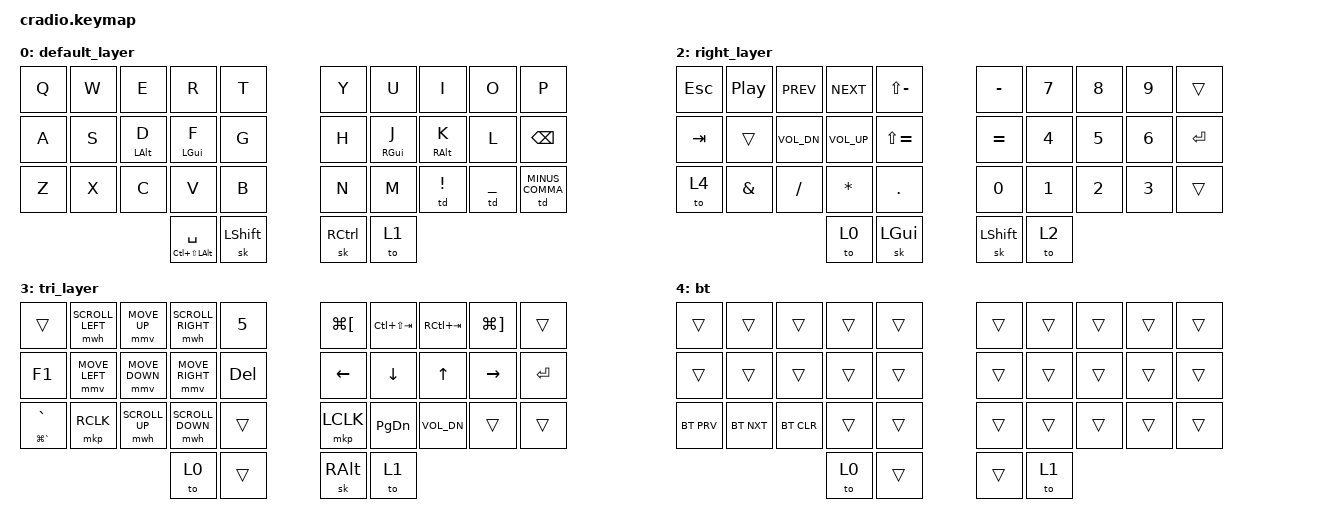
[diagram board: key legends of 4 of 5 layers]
/*
 * Copyright (c) 2020 The ZMK Contributors
 *
 * SPDX-License-Identifier: MIT
 */

#include <behaviors.dtsi>
#include <dt-bindings/zmk/keys.h>
#include <dt-bindings/zmk/bt.h>
#include <dt-bindings/zmk/mouse.h>

/* Configure behavior for mod-tap (mt) keys */
&mt {
    flavor = "tap-preferred";
    tapping_term_ms = <200>;
};

/* Configure behavior for mouse movement */
&mmv {
   time-to-max-speed-ms = <680>;
   acceleration-exponent=<2>;
};

/ {

    /* Define custom behaviors */
    behaviors {
        hm: homerow_mods {
            compatible = "zmk,behavior-hold-tap";
            label = "HOMEROW_MODS";
            #binding-cells = <2>;
            tapping-term-ms = <200>;
            quick_tap_ms = <0>;
            flavor = "tap-preferred";
            bindings = <&kp>, <&kp>;
        };
        td: tapdance {
            compatible = "zmk,behavior-hold-tap";
            label = "TAPDANCE";
            #binding-cells = <2>;
            tapping-term-ms = <150>;
            quick_tap_ms = <0>;
            flavor = "tap-preferred";
            bindings = <&kp>, <&kp>;
        };
    };

    /* Define the keymap */
    keymap {
        compatible = "zmk,keymap";

        /* Default layer - QWERTY layout with some modifiers */
        default_layer {
        /* 
         * ┌─────────┬─────────┬─────────┬─────────┬─────────┐            ┌─────────┬─────────┬─────────┬─────────┬─────────┐
         * │    Q    │    W    │    E    │    R    │    T    │            │    Y    │    U    │    I    │    O    │    P    │
         * ├─────────┼─────────┼─────────┼─────────┼─────────┤            ├─────────┼─────────┼─────────┼─────────┼─────────┤
         * │    A    │    S    │  Alt/D  │  GUI/F  │    G    │            │    H    │  GUI/J  │  Alt/K  │    L    │  Bksp   │
         * ├─────────┼─────────┼─────────┼─────────┼─────────┤            ├─────────┼─────────┼─────────┼─────────┼─────────┤
         * │    Z    │    X    │    C    │    V    │    B    │            │    N    │    M    │    !    │    _    │   - ,   │
         * └─────────┴─────────┴─────────┴─────────┴─────────┘            └─────────┴─────────┴─────────┴─────────┴─────────┘
         *                 LCtrl/Tap     Space/Tap                                LShift                RCtrl    Layer 1
         */

        bindings = <

        /* Row 1 */
        &kp Q      &kp W      &kp E      &kp R      &kp T              &kp Y      &kp U      &kp I      &kp O      &kp P
        
        /* Row 2 */
        &kp A      &kp S      &hm LALT D &hm LGUI F &kp G              &kp H      &hm RGUI J &hm RALT K &kp L      &kp BKSP

        /* Row 3 */
        &kp Z      &kp X      &kp C      &kp V      &kp B              &kp N      &kp M      &td EXCL   &td UNDERSCORE &td MINUS_COMMA

        /* Bottom row */
                          &mt LC(LS(LALT)) SPC &sk LSHIFT              &sk RCTRL  &to 1
        >;
        };

        /* Left-hand layer for special characters and numbers */
        left_layer {
        /* 
         * ┌─────────┬─────────┬─────────┬─────────┬─────────┐            ┌─────────┬─────────┬─────────┬─────────┬─────────┐
         * │   Esc   │    @    │   #3    │   $     │    %    │            │   ^     │    ,    │    .    │    ;    │  Bksp   │
         * ├─────────┼─────────┼─────────┼─────────┼─────────┤            ├─────────┼─────────┼─────────┼─────────┼─────────┤
         * │   Tab   │   =     │   [     │   {     │    '    │            │   \     │    [    │    ]    │   |     │  Enter  │
         * ├─────────┼─────────┼─────────┼─────────┼─────────┤            ├─────────┼─────────┼─────────┼─────────┼─────────┤
         * │   ~     │    3    │   {     │   }     │    "    │            │   (     │    )    │    ]    │   -> L3 │
         * └─────────┴─────────┴─────────┴─────────┴─────────┘            └─────────┴─────────┴─────────┴─────────┴─────────┘
         *               Layer 0         Shift                                RAlt      Layer 2
         */
        bindings = <
        &kp ESC     &kp ATSN  &td LC(LG(LS(N4))) LS(N3) &kp DLLR    &kp PRCNT  
        &kp CARET   &kp LS(COMMA) &kp LS(DOT)  &kp SEMI   &kp BKSP

        &kp TAB     &kp EQUAL &kp LA(RBKT)    &kp LA(LS(RBKT))  &kp SQT   
        &kp BSLH    &kp LBRC  &kp RBRC        &kp PIPE          &kp ENTER

        &kp TILDE   &kp LA(N3) &kp LA(LBKT)   &kp LA(LS(LBKT))  &kp DQT  
        &kp LBKT    &kp LPRN  &kp RPRN        &kp RBKT          &to 3

                          &to 0              &sk LSHIFT        &sk RALT          &to 2
        >;
        };

        /* Right-hand layer for media controls and navigation */
        right_layer {
        /* 
         * ┌─────────┬─────────┬─────────┬─────────┬─────────┐            ┌─────────┬─────────┬─────────┬─────────┬─────────┐
         * │   Esc   │   PP    │  Prev   │  Next   │    _    │            │    -    │    7    │    8    │    9    │   ->    │
         * ├─────────┼─────────┼─────────┼─────────┼─────────┤            ├─────────┼─────────┼─────────┼─────────┼─────────┤
         * │   Tab   │         │  Vol-   │  Vol+   │    =    │            │   =     │    4    │    5    │    6    │  Enter  │
         * ├─────────┼─────────┼─────────┼─────────┼─────────┤            ├─────────┼─────────┼─────────┼─────────┼─────────┤
         * │  -> L4  │   &     │    /    │    *    │    .    │            │    0    │    1    │    2    │    3    │   ->    │
         * └─────────┴─────────┴─────────┴─────────┴─────────┘            └─────────┴─────────┴─────────┴─────────┴─────────┘
         *               Layer 0      LGUI                                   Shift   Layer 2
         */
        bindings = <
        &kp ESC     &kp C_PP  &kp C_PREV &kp C_NEXT  &kp LS(MINUS)   
        &kp MINUS   &kp N7    &kp N8     &kp N9      &trans

        &kp TAB     &trans    &kp C_VOL_DN &kp C_VOL_UP &kp LS(EQUAL)  
        &kp EQUAL   &kp N4    &kp N5     &kp N6      &kp ENTER

        &to 4       &kp AMPS  &kp SLASH  &kp STAR    &kp DOT   
        &kp N0      &kp N1    &kp N2     &kp N3      &trans

                       &to 0              &sk LGUI    &sk LSHIFT        &to 2
        >;
        };

        /* Tri-layer with mouse controls */
        tri_layer {
        /* 
         * ┌─────────┬───────────────┬───────────────┬───────────────┬─────────┐            ┌──────────────┬──────────────┬──────────────┬──────────────┬─────────┐
         * │   ->    │ Scroll Left   │    Up         │ Scroll Right  │    5    │            │   [          │    Tab Left │    Tab Right │   ]          │   ->    │
         * ├─────────┼───────────────┼───────────────┼───────────────┼─────────┤            ├──────────────┼──────────────┼──────────────┼──────────────┼─────────┤
         * │   F1    │ Left          │ Down          │ Right         │  Del    │            │   Left        │    Down     │     Up       │   Right      │  Enter  │
         * ├─────────┼───────────────┼───────────────┼───────────────┼─────────┤            ├──────────────┼──────────────┼──────────────┼──────────────┼─────────┤
         * │ ` / ~   │ Right Click   │ Scroll Up     │ Scroll Down   │   ->    │            │ Left Click    │    PgDn      │  Vol Down    │   ->         │   ->    │
         * └─────────┴───────────────┴───────────────┴───────────────┴─────────┘            └──────────────┴──────────────┴──────────────┴──────────────┴─────────┘
         *                  Layer 0                                  RAlt                                   Layer 1
         */
        bindings = <
        &trans      &mwh SCROLL_LEFT  &mmv MOVE_UP &mwh SCROLL_RIGHT &kp NUM_5   
        &kp LG(LBKT)  &kp LC(LS(TAB))  &kp RC(TAB)  &kp LG(RBKT) &trans

        &kp F1      &mmv MOVE_LEFT  &mmv MOVE_DOWN &mmv MOVE_RIGHT  &kp DEL  
        &kp LEFT    &kp DOWN   &kp UP   &kp RIGHT   &kp ENTER

        &td LG(GRAVE) GRAVE &mkp RCLK &mwh SCROLL_UP  &mwh SCROLL_DOWN &trans  
        &mkp LCLK  &kp PG_DN &kp K_VOL_DN &trans     &trans

                       &to 0              &trans   &sk RALT           &to 1
        >;
        };

        /* Bluetooth layer */
        bt {
        /*
         * This layer controls Bluetooth functions, like switching between devices.
         * 
         * ┌─────────┬─────────┬─────────┬─────────┬─────────┐            ┌─────────┬─────────┬─────────┬─────────┬─────────┐
         * │         │         │         │         │         │            │         │         │         │         │         │
         * ├─────────┼─────────┼─────────┼─────────┼─────────┤            ├─────────┼─────────┼─────────┼─────────┼─────────┤
         * │         │         │         │         │         │            │         │         │         │         │         │
         * ├─────────┼─────────┼─────────┼─────────┼─────────┤            ├─────────┼─────────┼─────────┼─────────┼─────────┤
         * │ BT Prev │ BT Next │ BT Clear│         │         │            │         │         │         │         │         │
         * └─────────┴─────────┴─────────┴─────────┴─────────┘            └─────────┴─────────┴─────────┴─────────┴─────────┘
         *               Layer 0                                               Layer 1
         */
        bindings = <
        &trans  &trans &trans &trans &trans &trans &trans &trans &trans &trans
        &trans  &trans &trans &trans &trans &trans &trans &trans &trans &trans
        &bt BT_PRV  &bt BT_NXT &bt BT_CLR &trans &trans &trans &trans &trans &trans &trans
                      &to 0              &trans   &trans            &to 1
        >;
        };

    };
};
